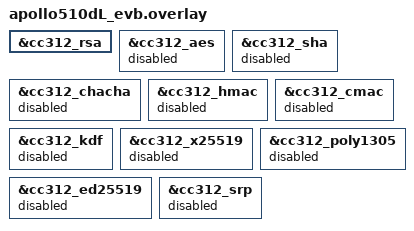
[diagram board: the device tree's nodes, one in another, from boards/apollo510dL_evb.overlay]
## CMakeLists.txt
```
# Copyright (c) 2026 Ambiq Micro, Inc.
# SPDX-License-Identifier: Apache-2.0

cmake_minimum_required(VERSION 3.20.0)
find_package(Zephyr REQUIRED HINTS $ENV{ZEPHYR_BASE})
project(rsa_hal_example)

target_sources(app PRIVATE src/main.c)
```

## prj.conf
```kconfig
# Copyright (c) 2026 Ambiq Micro, Inc.
# SPDX-License-Identifier: Apache-2.0

CONFIG_CONSOLE=y
CONFIG_SERIAL=y
CONFIG_PRINTK=y
CONFIG_CRYPTO=y
CONFIG_CRYPTO_AMBIQ_RSA=y
CONFIG_NOCACHE_MEMORY=y
CONFIG_MAIN_STACK_SIZE=12288
```

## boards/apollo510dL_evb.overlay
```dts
/*
 * Copyright (c) 2026 Ambiq Micro, Inc.
 * SPDX-License-Identifier: Apache-2.0
 */

&cc312_rsa {
	status = "okay";
};

&cc312_aes {
	status = "disabled";
};

&cc312_sha {
	status = "disabled";
};

&cc312_chacha {
	status = "disabled";
};

&cc312_hmac {
	status = "disabled";
};

&cc312_cmac {
	status = "disabled";
};

&cc312_kdf {
	status = "disabled";
};

&cc312_x25519 {
	status = "disabled";
};

&cc312_poly1305 {
	status = "disabled";
};

&cc312_ed25519 {
	status = "disabled";
};

&cc312_srp {
	status = "disabled";
};
```

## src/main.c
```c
/*
 * Copyright (c) 2026 Ambiq Micro, Inc.
 *
 * SPDX-License-Identifier: Apache-2.0
 */

#include <zephyr/device.h>
#include <zephyr/drivers/crypto/crypto_ambiq_rsa.h>
#include <zephyr/kernel.h>
#include <zephyr/linker/section_tags.h>
#include <zephyr/sys/printk.h>

#include <string.h>

#include <soc.h>

#define RSA_DEV DEVICE_DT_GET_ONE(ambiq_crypto_rsa)

#define RSA_MOD_BYTES 32U

#if IS_ENABLED(CONFIG_NOCACHE_MEMORY)
#define RSA_NOCACHE __nocache
#else
#define RSA_NOCACHE
#endif

static RSA_NOCACHE uint8_t g_result[RSA_MOD_BYTES] __aligned(32);

/*
 * 256-bit modexp KAT: 42^65537 mod n, with a full-width odd modulus
 * (2^256 - 59). Leading-zero-padded moduli undersize the PKA Barrett length.
 */
static const uint8_t modulus[RSA_MOD_BYTES] = {
	0xff, 0xff, 0xff, 0xff, 0xff, 0xff, 0xff, 0xff, 0xff, 0xff, 0xff,
	0xff, 0xff, 0xff, 0xff, 0xff, 0xff, 0xff, 0xff, 0xff, 0xff, 0xff,
	0xff, 0xff, 0xff, 0xff, 0xff, 0xff, 0xff, 0xff, 0xff, 0xc5,
};
static const uint8_t exponent[RSA_MOD_BYTES] = {
	0x00, 0x00, 0x00, 0x00, 0x00, 0x00, 0x00, 0x00, 0x00, 0x00, 0x00,
	0x00, 0x00, 0x00, 0x00, 0x00, 0x00, 0x00, 0x00, 0x00, 0x00, 0x00,
	0x00, 0x00, 0x00, 0x00, 0x00, 0x00, 0x00, 0x01, 0x00, 0x01,
};
static const uint8_t base[RSA_MOD_BYTES] = {
	0x00, 0x00, 0x00, 0x00, 0x00, 0x00, 0x00, 0x00, 0x00, 0x00, 0x00,
	0x00, 0x00, 0x00, 0x00, 0x00, 0x00, 0x00, 0x00, 0x00, 0x00, 0x00,
	0x00, 0x00, 0x00, 0x00, 0x00, 0x00, 0x00, 0x00, 0x00, 0x2a,
};
static const uint8_t result_exp[RSA_MOD_BYTES] = {
	0xe5, 0x6b, 0xab, 0x23, 0x26, 0xfa, 0xdc, 0x8c, 0x2c, 0x3b, 0x96,
	0x40, 0x65, 0x8c, 0xb5, 0x1f, 0x3e, 0x3e, 0x74, 0xd1, 0xaf, 0xba,
	0x1e, 0xb8, 0x51, 0x36, 0x18, 0x80, 0xab, 0x3e, 0x11, 0x45,
};

int main(void)
{
	const struct device *dev = RSA_DEV;
	struct crypto_ambiq_rsa_mod_exp_pkt pkt = {
		.modulus = modulus,
		.modulus_bytes = RSA_MOD_BYTES,
		.exponent = exponent,
		.base = base,
		.result = g_result,
	};
	int ret;
	bool ok;

	printk("\nAmbiq CC312 RSA driver checks\n\n");

	if (!device_is_ready(dev)) {
		printk("RSA device not ready\n");
		return 0;
	}

	am_hal_cc312_context_clear(g_result, sizeof(g_result));
	ret = crypto_ambiq_rsa_mod_exp(dev, &pkt);
	ok = (ret == 0) && (memcmp(g_result, result_exp, sizeof(result_exp)) == 0);

	printk("RSA modexp 256-bit vector               %s\n", ok ? "PASS" : "FAIL");

	if (ok) {
		printk("All driver checks passed\n");
	}

	return 0;
}
```
